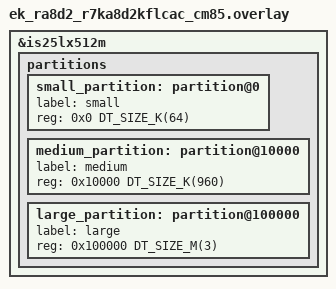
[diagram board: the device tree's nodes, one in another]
/*
 * Copyright (c) 2026 Renesas Electronics Corporation
 * SPDX-License-Identifier: Apache-2.0
 */

/delete-node/ &storage_partition;

&is25lx512m {
	partitions {
		/delete-node/ partition;

		small_partition: partition@0 {
			label = "small";
			reg = <0x0 DT_SIZE_K(64)>;
		};

		medium_partition: partition@10000 {
			label = "medium";
			reg = <0x10000 DT_SIZE_K(960)>;
		};

		large_partition: partition@100000 {
			label = "large";
			reg = <0x100000 DT_SIZE_M(3)>;
		};
	};
};
